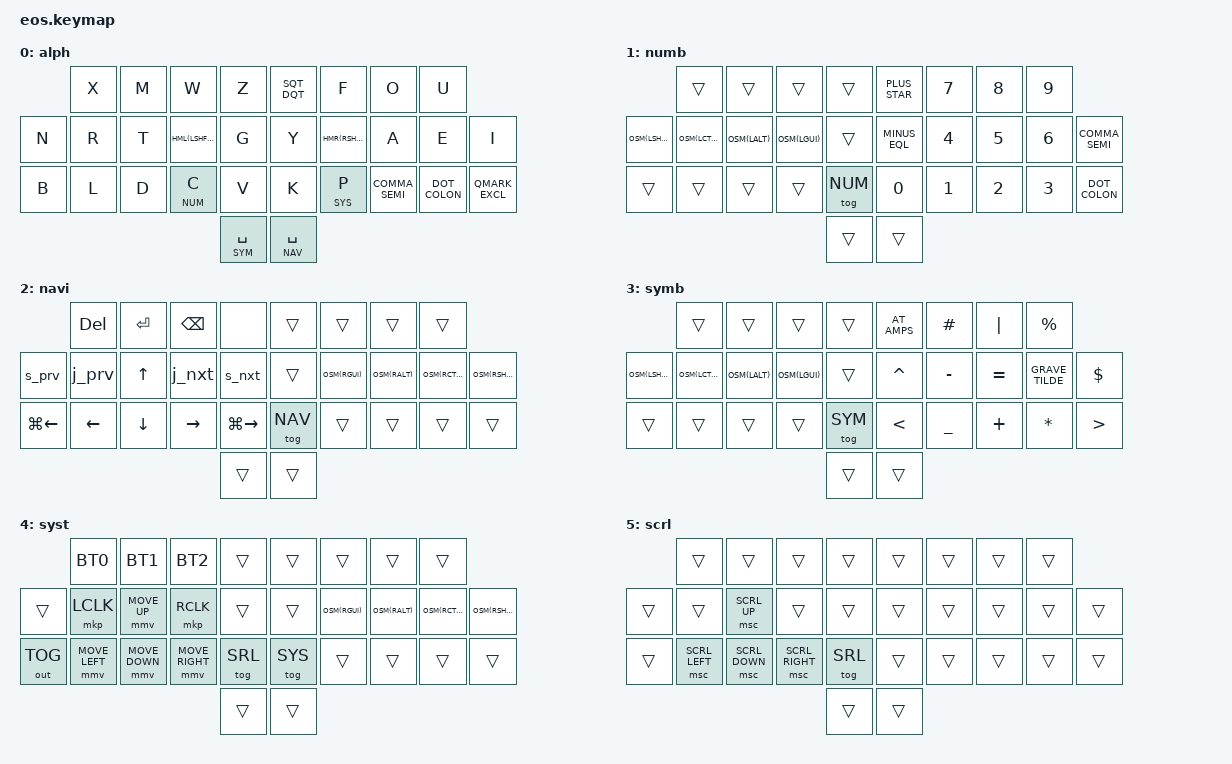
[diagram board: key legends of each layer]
#include <behaviors.dtsi>
#include <dt-bindings/zmk/bt.h>
#include <dt-bindings/zmk/keys.h>
#include <dt-bindings/zmk/outputs.h>
#include <dt-bindings/zmk/pointing.h>

/* Layer Definitions */
#define ALP 0
#define NUM 1
#define NAV 2
#define SYM 3
#define SYS 4
#define SRL 5
#define ALL ALP SYM NAV NUM SYS SRL
/* ---------------- */

#include "zmk-helpers/helper.h"
#include "includes/keylabels.h"
#include "includes/behaviors.dtsi"  // Requires key-labels.
#include "includes/combos.dtsi"     // Requires behaviors.

#define XXX &none
#define ___ &trans

/* Global Overrides */
&lt {
    flavor = "balanced";
    quick-tap-ms=<175>;
    tapping-term-ms=<200>;
    retro-tap;
};

/* Haptic Behaviors */
/ {
    HAPTIC_KEYCODE(haptic_lshft, <0xE1>, <&haptic_click_l>, <ALP>)
    HAPTIC_KEYCODE(haptic_rshft, <0xE5>, <&haptic_click_r>, <ALP>)

    /* OSM position-based haptic */
    HAPTIC_POSITION(haptic_osm_lm4, <LM4>, <&haptic_click_l>, <NUM SYM>)
    HAPTIC_POSITION(haptic_osm_lm3, <LM3>, <&haptic_click_l>, <NUM SYM>)
    HAPTIC_POSITION(haptic_osm_lm2, <LM2>, <&haptic_click_l>, <NUM SYM>)
    HAPTIC_POSITION(haptic_osm_lm1, <LM1>, <&haptic_click_l>, <NUM SYM>)
    HAPTIC_POSITION(haptic_osm_rm1, <RM1>, <&haptic_click_r>, <NAV SYS>)
    HAPTIC_POSITION(haptic_osm_rm2, <RM2>, <&haptic_click_r>, <NAV SYS>)
    HAPTIC_POSITION(haptic_osm_rm3, <RM3>, <&haptic_click_r>, <NAV SYS>)
    HAPTIC_POSITION(haptic_osm_rm4, <RM4>, <&haptic_click_r>, <NAV SYS>)
};
/* ----------- */

/* Auto-Shift Symbols */
#define COMMA_SEMI  AS_2(COMMA, SEMI)
#define DOT_COLON   AS_2(DOT, COLON)
#define QMARK_EXCL  AS_2(QMARK, EXCL)
#define AT_AMPS     AS_2(AT, AMPS)
#define GRAVE_TILDE AS_2(GRAVE, TILDE)
#define MINUS_EQL   AS_2(MINUS, EQUAL)
#define PLUS_STAR   AS_2(PLUS, STAR)
#define SQT_DQT     AS_2(SQT, DQT)
/* ----------- */

ZMK_TRI_STATE(win_swap, bindings=<&kt LGUI>,<&kp TAB>,<&kt LGUI>;)
ZMK_TRI_STATE(tab_swap, bindings=<&kt LCTRL>,<&kp TAB>,<&kt LCTRL>;)

/* Layers */
ZMK_LAYER(alph,
//  ╭─────────────┬─────────────┬─────────────┬─────────────┬─────────────╮  ╭─────────────┬─────────────┬─────────────┬─────────────┬─────────────╮
                    &kp X         &kp M         &kp W         &kp Z            SQT_DQT       &kp F         &kp O         &kp U
//  ├─────────────┼─────────────┼─────────────┼─────────────┼─────────────┤  ├─────────────┼─────────────┼─────────────┼─────────────┼─────────────┤
      &kp N         &kp R         &kp T         HML(LSHFT,S)  &kp G            &kp Y         HMR(RSHFT,H)  &kp A         &kp E         &kp I
//  ├─────────────┼─────────────┼─────────────┼─────────────┼─────────────┤  ├─────────────┼─────────────┼─────────────┼─────────────┼─────────────┤
      &kp B         &kp L         &kp D         &lt NUM C     &kp V            &kp K         &lt SYS P     COMMA_SEMI    DOT_COLON     QMARK_EXCL
//  ╰─────────────┼─────────────┴─────────────┼─────────────┼─────────────┤  ├─────────────┤─────────────┼─────────────┴─────────────┼─────────────╯
                                                             &lt SYM SPACE    &lt NAV SPACE
//                                                          ╰─────────────╯  ╰─────────────╯
)

ZMK_LAYER(numb,
//  ╭─────────────┬─────────────┬─────────────┬─────────────┬─────────────╮  ╭─────────────┬─────────────┬─────────────┬─────────────┬─────────────╮
                    ___           ___           ___           ___              PLUS_STAR     &kp N7        &kp N8        &kp N9
//  ├─────────────┼─────────────┼─────────────┼─────────────┼─────────────┤  ├─────────────┼─────────────┼─────────────┼─────────────┼─────────────┤
      OSM(LSHFT)    OSM(LCTRL)    OSM(LALT)     OSM(LGUI)     ___              MINUS_EQL     &kp N4        &kp N5        &kp N6        COMMA_SEMI
//  ├─────────────┼─────────────┼─────────────┼─────────────┼─────────────┤  ├─────────────┼─────────────┼─────────────┼─────────────┼─────────────┤
      ___           ___           ___           ___           &tog NUM         &kp N0        &kp N1        &kp N2        &kp N3        DOT_COLON
//  ╰─────────────┼─────────────┴─────────────┼─────────────┼─────────────┤  ├─────────────┤─────────────┼─────────────┴─────────────┼─────────────╯
                                                              ___              ___
//                                                          ╰─────────────╯  ╰─────────────╯
)

ZMK_LAYER(navi,
//  ╭─────────────┬─────────────┬─────────────┬─────────────┬─────────────╮  ╭─────────────┬─────────────┬─────────────┬─────────────┬─────────────╮
                    &kp DEL       &kp ENTER     &kp BSPC      XXX              ___           ___           ___           ___
//  ├─────────────┼─────────────┼─────────────┼─────────────┼─────────────┤  ├─────────────┼─────────────┼─────────────┼─────────────┼─────────────┤
      &s_prv        &j_prv        &kp UP        &j_nxt        &s_nxt           ___           OSM(RGUI)     OSM(RALT)     OSM(RCTRL)    OSM(RSHFT)
//  ├─────────────┼─────────────┼─────────────┼─────────────┼─────────────┤  ├─────────────┼─────────────┼─────────────┼─────────────┼─────────────┤
      &kp LG(LEFT)  &kp LEFT      &kp DOWN      &kp RIGHT     &kp LG(RIGHT)     &tog NAV      ___           ___           ___           ___
//  ╰─────────────┼─────────────┴─────────────┼─────────────┼─────────────┤  ├─────────────┤─────────────┼─────────────┴─────────────┼─────────────╯
                                                              ___              ___
//                                                          ╰─────────────╯  ╰─────────────╯
)

ZMK_LAYER(symb,
//  ╭─────────────┬─────────────┬─────────────┬─────────────┬─────────────╮  ╭─────────────┬─────────────┬─────────────┬─────────────┬─────────────╮
                    ___           ___           ___           ___              AT_AMPS       &kp HASH      &kp PIPE      &kp PRCNT
//  ├─────────────┼─────────────┼─────────────┼─────────────┼─────────────┤  ├─────────────┼─────────────┼─────────────┼─────────────┼─────────────┤
      OSM(LSHFT)    OSM(LCTRL)    OSM(LALT)     OSM(LGUI)     ___              &kp CARET     &kp MINUS     &kp EQUAL     GRAVE_TILDE   &kp DLLR
//  ├─────────────┼─────────────┼─────────────┼─────────────┼─────────────┤  ├─────────────┼─────────────┼─────────────┼─────────────┼─────────────┤
      ___           ___           ___           ___           &tog SYM         &kp LT        &kp UNDER     &kp PLUS      &kp STAR      &kp GT
//  ╰─────────────┼─────────────┴─────────────┼─────────────┼─────────────┤  ├─────────────┤─────────────┼─────────────┴─────────────┼─────────────╯
                                                              ___              ___
//                                                          ╰─────────────╯  ╰─────────────╯
)

ZMK_LAYER(syst,
//  ╭─────────────┬─────────────┬─────────────┬─────────────┬─────────────╮  ╭─────────────┬─────────────┬─────────────┬─────────────┬─────────────╮
                    BT0           BT1           BT2           ___              ___           ___           ___           ___
//  ├─────────────┼─────────────┼─────────────┼─────────────┼─────────────┤  ├─────────────┼─────────────┼─────────────┼─────────────┼─────────────┤
      ___           &mkp LCLK     &mmv MOVE_UP  &mkp RCLK     ___              ___           OSM(RGUI)     OSM(RALT)     OSM(RCTRL)    OSM(RSHFT)
//  ├─────────────┼─────────────┼─────────────┼─────────────┼─────────────┤  ├─────────────┼─────────────┼─────────────┼─────────────┼─────────────┤
     &out OUT_TOG &mmv MOVE_LEFT &mmv MOVE_DOWN &mmv MOVE_RIGHT &tog SRL       &tog SYS      ___           ___           ___           ___
//  ╰─────────────┼─────────────┴─────────────┼─────────────┼─────────────┤  ├─────────────┤─────────────┼─────────────┴─────────────┼─────────────╯
                                                              ___              ___
//                                                          ╰─────────────╯  ╰─────────────╯
)

ZMK_LAYER(scrl,
//  ╭─────────────┬─────────────┬─────────────┬─────────────┬─────────────╮  ╭─────────────┬─────────────┬─────────────┬─────────────┬─────────────╮
                    ___           ___           ___           ___              ___           ___           ___           ___
//  ├─────────────┼─────────────┼─────────────┼─────────────┼─────────────┤  ├─────────────┼─────────────┼─────────────┼─────────────┼─────────────┤
      ___           ___           &msc SCRL_UP  ___           ___              ___           ___           ___           ___           ___
//  ├─────────────┼─────────────┼─────────────┼─────────────┼─────────────┤  ├─────────────┼─────────────┼─────────────┼─────────────┼─────────────┤
      ___         &msc SCRL_LEFT &msc SCRL_DOWN &msc SCRL_RIGHT &tog SRL       ___           ___           ___           ___           ___
//  ╰─────────────┼─────────────┴─────────────┼─────────────┼─────────────┤  ├─────────────┤─────────────┼─────────────┴─────────────┼─────────────╯
                                                              ___              ___
//                                                          ╰─────────────╯  ╰─────────────╯
)
/* ----------- */
